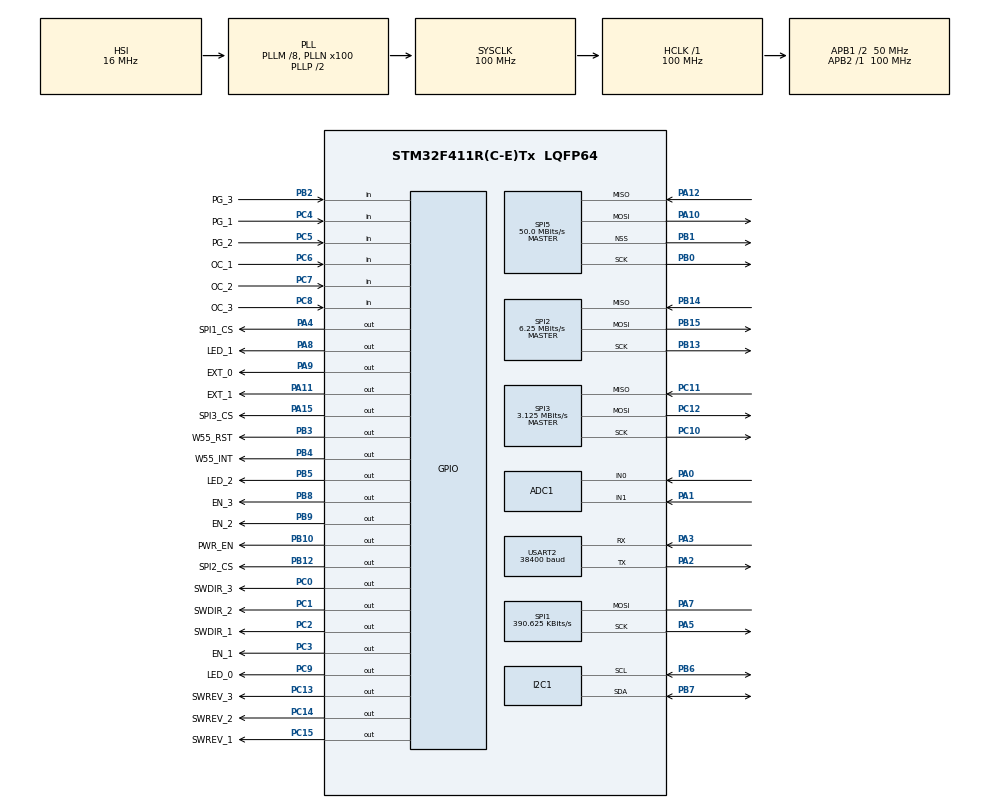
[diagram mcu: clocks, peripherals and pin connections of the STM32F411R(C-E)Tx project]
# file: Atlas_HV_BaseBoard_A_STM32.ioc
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ADC1.Channel-3\#ChannelRegularConversion=ADC_CHANNEL_0
ADC1.NbrOfConversionFlag=1
ADC1.Rank-3\#ChannelRegularConversion=1
ADC1.SamplingTime-3\#ChannelRegularConversion=ADC_SAMPLETIME_3CYCLES
ADC1.master=1
Mcu.Family=STM32F4
Mcu.Name=STM32F411R(C-E)Tx
Mcu.Package=LQFP64
NVIC.PriorityGroup=NVIC_PRIORITYGROUP_4
NVIC.TIM1_UP_TIM10_IRQn=true\:0\:0\:false\:false\:true\:true\:true\:true
NVIC.USART2_IRQn=true\:0\:0\:false\:false\:true\:true\:false\:true
PA0-WKUP.Signal=ADCx_IN0
PA1.Signal=ADCx_IN1
PA10.Mode=Full_Duplex_Master
PA10.Signal=SPI5_MOSI
PA11.GPIO_Label=EXT_1
PA11.Signal=GPIO_Output
PA12.Mode=Full_Duplex_Master
PA12.Signal=SPI5_MISO
PA15.GPIO_Label=SPI3_CS
PA15.Signal=GPIO_Output
PA2.Mode=Asynchronous
PA2.Signal=USART2_TX
PA3.Mode=Asynchronous
PA3.Signal=USART2_RX
PA4.GPIO_Label=SPI1_CS
PA4.Signal=GPIO_Output
PA5.Mode=Simplex_Bidirectional_Master
PA5.Signal=SPI1_SCK
PA7.Mode=Simplex_Bidirectional_Master
PA7.Signal=SPI1_MOSI
PA8.GPIO_Label=LED_1
PA8.Signal=GPIO_Output
PA9.GPIO_Label=EXT_0
PA9.Signal=GPIO_Output
PB0.Mode=Full_Duplex_Master
PB0.Signal=SPI5_SCK
PB1.Mode=NSS_Signal_Hard_Output
PB1.Signal=SPI5_NSS
PB10.GPIO_Label=PWR_EN
PB10.Signal=GPIO_Output
PB12.GPIO_Label=SPI2_CS
PB12.Signal=GPIO_Output
PB13.Mode=Full_Duplex_Master
PB13.Signal=SPI2_SCK
PB14.Mode=Full_Duplex_Master
PB14.Signal=SPI2_MISO
PB15.Mode=Full_Duplex_Master
PB15.Signal=SPI2_MOSI
PB2.GPIO_Label=PG_3
PB2.Signal=GPIO_Input
PB3.GPIO_Label=W55_RST
PB3.Signal=GPIO_Output
PB4.GPIO_Label=W55_INT
PB4.Signal=GPIO_Output
PB5.GPIO_Label=LED_2
PB5.Signal=GPIO_Output
PB6.Mode=I2C
PB6.Signal=I2C1_SCL
PB7.Mode=I2C
PB7.Signal=I2C1_SDA
PB8.GPIO_Label=EN_3
PB8.Signal=GPIO_Output
PB9.GPIO_Label=EN_2
PB9.Signal=GPIO_Output
PC0.GPIO_Label=SWDIR_3
PC0.Signal=GPIO_Output
PC1.GPIO_Label=SWDIR_2
PC1.Signal=GPIO_Output
PC10.Mode=Full_Duplex_Master
PC10.Signal=SPI3_SCK
PC11.Mode=Full_Duplex_Master
PC11.Signal=SPI3_MISO
PC12.Mode=Full_Duplex_Master
PC12.Signal=SPI3_MOSI
PC13-ANTI_TAMP.GPIO_Label=SWREV_3
PC13-ANTI_TAMP.Signal=GPIO_Output
PC14-OSC32_IN.GPIO_Label=SWREV_2
PC14-OSC32_IN.Signal=GPIO_Output
PC15-OSC32_OUT.GPIO_Label=SWREV_1
PC15-OSC32_OUT.Signal=GPIO_Output
PC2.GPIO_Label=SWDIR_1
PC2.Signal=GPIO_Output
PC3.GPIO_Label=EN_1
PC3.Signal=GPIO_Output
PC4.GPIO_Label=PG_1
PC4.Signal=GPIO_Input
PC5.GPIO_Label=PG_2
PC5.Signal=GPIO_Input
PC6.GPIO_Label=OC_1
PC6.Signal=GPIO_Input
PC7.GPIO_Label=OC_2
PC7.Signal=GPIO_Input
PC8.GPIO_Label=OC_3
PC8.Signal=GPIO_Input
PC9.GPIO_Label=LED_0
PC9.Signal=GPIO_Output
ProjectManager.HeapSize=0x200
ProjectManager.StackSize=0x400
ProjectManager.TargetToolchain=STM32CubeIDE
RCC.48MHZClocksFreq_Value=50000000
RCC.AHBFreq_Value=100000000
RCC.APB1CLKDivider=RCC_HCLK_DIV2
RCC.APB1Freq_Value=50000000
RCC.APB1TimFreq_Value=100000000
RCC.APB2Freq_Value=100000000
RCC.APB2TimFreq_Value=100000000
RCC.CortexFreq_Value=100000000
RCC.HCLKFreq_Value=100000000
RCC.HSE_VALUE=25000000
RCC.HSI_VALUE=16000000
RCC.LSE_VALUE=32768
RCC.PLLM=8
RCC.PLLN=100
RCC.SYSCLKFreq_VALUE=100000000
RCC.SYSCLKSource=RCC_SYSCLKSOURCE_PLLCLK
RCC.VCOOutputFreq_Value=200000000
SH.ADCx_IN0.0=ADC1_IN0,IN0
SH.ADCx_IN1.0=ADC1_IN1,IN1
SPI1.BaudRatePrescaler=SPI_BAUDRATEPRESCALER_256
SPI1.CLKPhase=SPI_PHASE_2EDGE
SPI1.CalculateBaudRate=390.625 KBits/s
SPI1.Direction=SPI_DIRECTION_1LINE
SPI1.Mode=SPI_MODE_MASTER
SPI1.VirtualType=VM_MASTER
SPI2.BaudRatePrescaler=SPI_BAUDRATEPRESCALER_8
SPI2.CalculateBaudRate=6.25 MBits/s
SPI2.DataSize=SPI_DATASIZE_16BIT
SPI2.Direction=SPI_DIRECTION_2LINES
SPI2.Mode=SPI_MODE_MASTER
SPI2.VirtualType=VM_MASTER
SPI3.BaudRatePrescaler=SPI_BAUDRATEPRESCALER_16
SPI3.CalculateBaudRate=3.125 MBits/s
SPI3.Direction=SPI_DIRECTION_2LINES
SPI3.Mode=SPI_MODE_MASTER
SPI3.VirtualType=VM_MASTER
SPI5.CalculateBaudRate=50.0 MBits/s
SPI5.Direction=SPI_DIRECTION_2LINES
SPI5.Mode=SPI_MODE_MASTER
SPI5.VirtualNSS=VM_NSSHARD
SPI5.VirtualType=VM_MASTER
TIM10.Period=1999
TIM10.Prescaler=99
USART2.BaudRate=38400
USART2.VirtualMode=VM_ASYNC
VP_TIM10_VS_ClockSourceINT.Mode=Enable_Timer
board=custom

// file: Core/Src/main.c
/* USER CODE BEGIN Header */
/**
  ******************************************************************************
  * @file           : main.c
  * @brief          : Main program body
  ******************************************************************************
  * @attention
  *
  * Copyright (c) 2023 STMicroelectronics.
  * All rights reserved.
  *
  * This software is licensed under terms that can be found in the LICENSE file
  * in the root directory of this software component.
  * If no LICENSE file comes with this software, it is provided AS-IS.
  *
  ******************************************************************************
  */
/* USER CODE END Header */
#include "main.h"
#include "adc.h"
#include "i2c.h"
#include "spi.h"
#include "tim.h"
#include "usart.h"
#include "gpio.h"

/* USER CODE BEGIN Includes */
#include "app__mainloop.h"
/* USER CODE END Includes */

void SystemClock_Config(void);

int main(void)
{

  /* MCU Configuration--------------------------------------------------------*/

  /* Reset of all peripherals, Initializes the Flash interface and the Systick. */
  HAL_Init();

  /* Configure the system clock */
  SystemClock_Config();

  /* Initialize all configured peripherals */
  MX_GPIO_Init();
  MX_ADC1_Init();
  MX_I2C1_Init();
  MX_SPI1_Init();
  MX_SPI2_Init();
  MX_SPI3_Init();
  MX_SPI5_Init();
  MX_USART2_UART_Init();
  MX_TIM10_Init();
  /* USER CODE BEGIN 2 */

  application_main();
  /* USER CODE END 2 */

  /* Infinite loop */
  while (1)
  {

  }
}

void SystemClock_Config(void)
{
  RCC_OscInitTypeDef RCC_OscInitStruct = {0};
  RCC_ClkInitTypeDef RCC_ClkInitStruct = {0};

  /** Configure the main internal regulator output voltage
  */
  __HAL_RCC_PWR_CLK_ENABLE();
  __HAL_PWR_VOLTAGESCALING_CONFIG(PWR_REGULATOR_VOLTAGE_SCALE1);

  /** Initializes the RCC Oscillators according to the specified parameters
  * in the RCC_OscInitTypeDef structure.
  */
  RCC_OscInitStruct.OscillatorType = RCC_OSCILLATORTYPE_HSI;
  RCC_OscInitStruct.HSIState = RCC_HSI_ON;
  RCC_OscInitStruct.HSICalibrationValue = RCC_HSICALIBRATION_DEFAULT;
  RCC_OscInitStruct.PLL.PLLState = RCC_PLL_ON;
  RCC_OscInitStruct.PLL.PLLSource = RCC_PLLSOURCE_HSI;
  RCC_OscInitStruct.PLL.PLLM = 8;
  RCC_OscInitStruct.PLL.PLLN = 100;
  RCC_OscInitStruct.PLL.PLLP = RCC_PLLP_DIV2;
  RCC_OscInitStruct.PLL.PLLQ = 4;
  if (HAL_RCC_OscConfig(&RCC_OscInitStruct) != HAL_OK)
  {
    Error_Handler();
  }

  /** Initializes the CPU, AHB and APB buses clocks
  */
  RCC_ClkInitStruct.ClockType = RCC_CLOCKTYPE_HCLK|RCC_CLOCKTYPE_SYSCLK
                              |RCC_CLOCKTYPE_PCLK1|RCC_CLOCKTYPE_PCLK2;
  RCC_ClkInitStruct.SYSCLKSource = RCC_SYSCLKSOURCE_PLLCLK;
  RCC_ClkInitStruct.AHBCLKDivider = RCC_SYSCLK_DIV1;
  RCC_ClkInitStruct.APB1CLKDivider = RCC_HCLK_DIV2;
  RCC_ClkInitStruct.APB2CLKDivider = RCC_HCLK_DIV1;

  if (HAL_RCC_ClockConfig(&RCC_ClkInitStruct, FLASH_LATENCY_3) != HAL_OK)
  {
    Error_Handler();
  }
}

void Error_Handler(void)
{
  __disable_irq();
  while (1)
  {
  }
}
